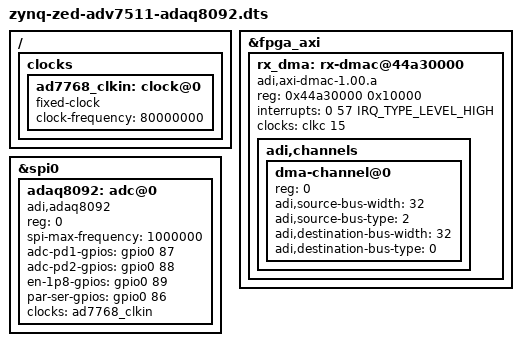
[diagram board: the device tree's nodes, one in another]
// SPDX-License-Identifier: GPL-2.0
/*
 * Analog Devices AD7768
 * https://wiki.analog.com/resources/tools-software/linux-drivers/iio-adc/ad7768
 *
 * hdl_project: <ad7768evb/zed>
 * board_revision: <>
 *
 * Copyright (C) 2016-2019 Analog Devices Inc.
 */
/dts-v1/;

#include "zynq-zed.dtsi"
#include "zynq-zed-adv7511.dtsi"
#include <dt-bindings/gpio/gpio.h>

/ {
	clocks {
		ad7768_clkin: clock@0 {
			#clock-cells = <0>;
			compatible = "fixed-clock";
			clock-frequency = <80000000>;
		};
	};
};

&fpga_axi {
	rx_dma: rx-dmac@44a30000 {
		compatible = "adi,axi-dmac-1.00.a";
		reg = <0x44a30000 0x10000>;
		#dma-cells = <1>;
		interrupts = <0 57 IRQ_TYPE_LEVEL_HIGH>;
		clocks = <&clkc 15>;

		adi,channels {
			#size-cells = <0>;
			#address-cells = <1>;

			dma-channel@0 {
				reg = <0>;
				adi,source-bus-width = <32>;
				adi,source-bus-type = <2>;
				adi,destination-bus-width = <32>;
				adi,destination-bus-type = <0>;
			};
		};
	};
};

&spi0 {
	status = "okay";

	adaq8092: adc@0 {
		compatible = "adi,adaq8092";
		reg = <0>;
		spi-max-frequency = <1000000>;

		adc-pd1-gpios = <&gpio0 87 GPIO_ACTIVE_HIGH>;
		adc-pd2-gpios = <&gpio0 88 GPIO_ACTIVE_HIGH>;
		en-1p8-gpios = <&gpio0 89 GPIO_ACTIVE_HIGH>;
		par-ser-gpios = <&gpio0 86 GPIO_ACTIVE_HIGH>;

		clocks = <&ad7768_clkin>;
		clock-names = "clkin";
	};
};
